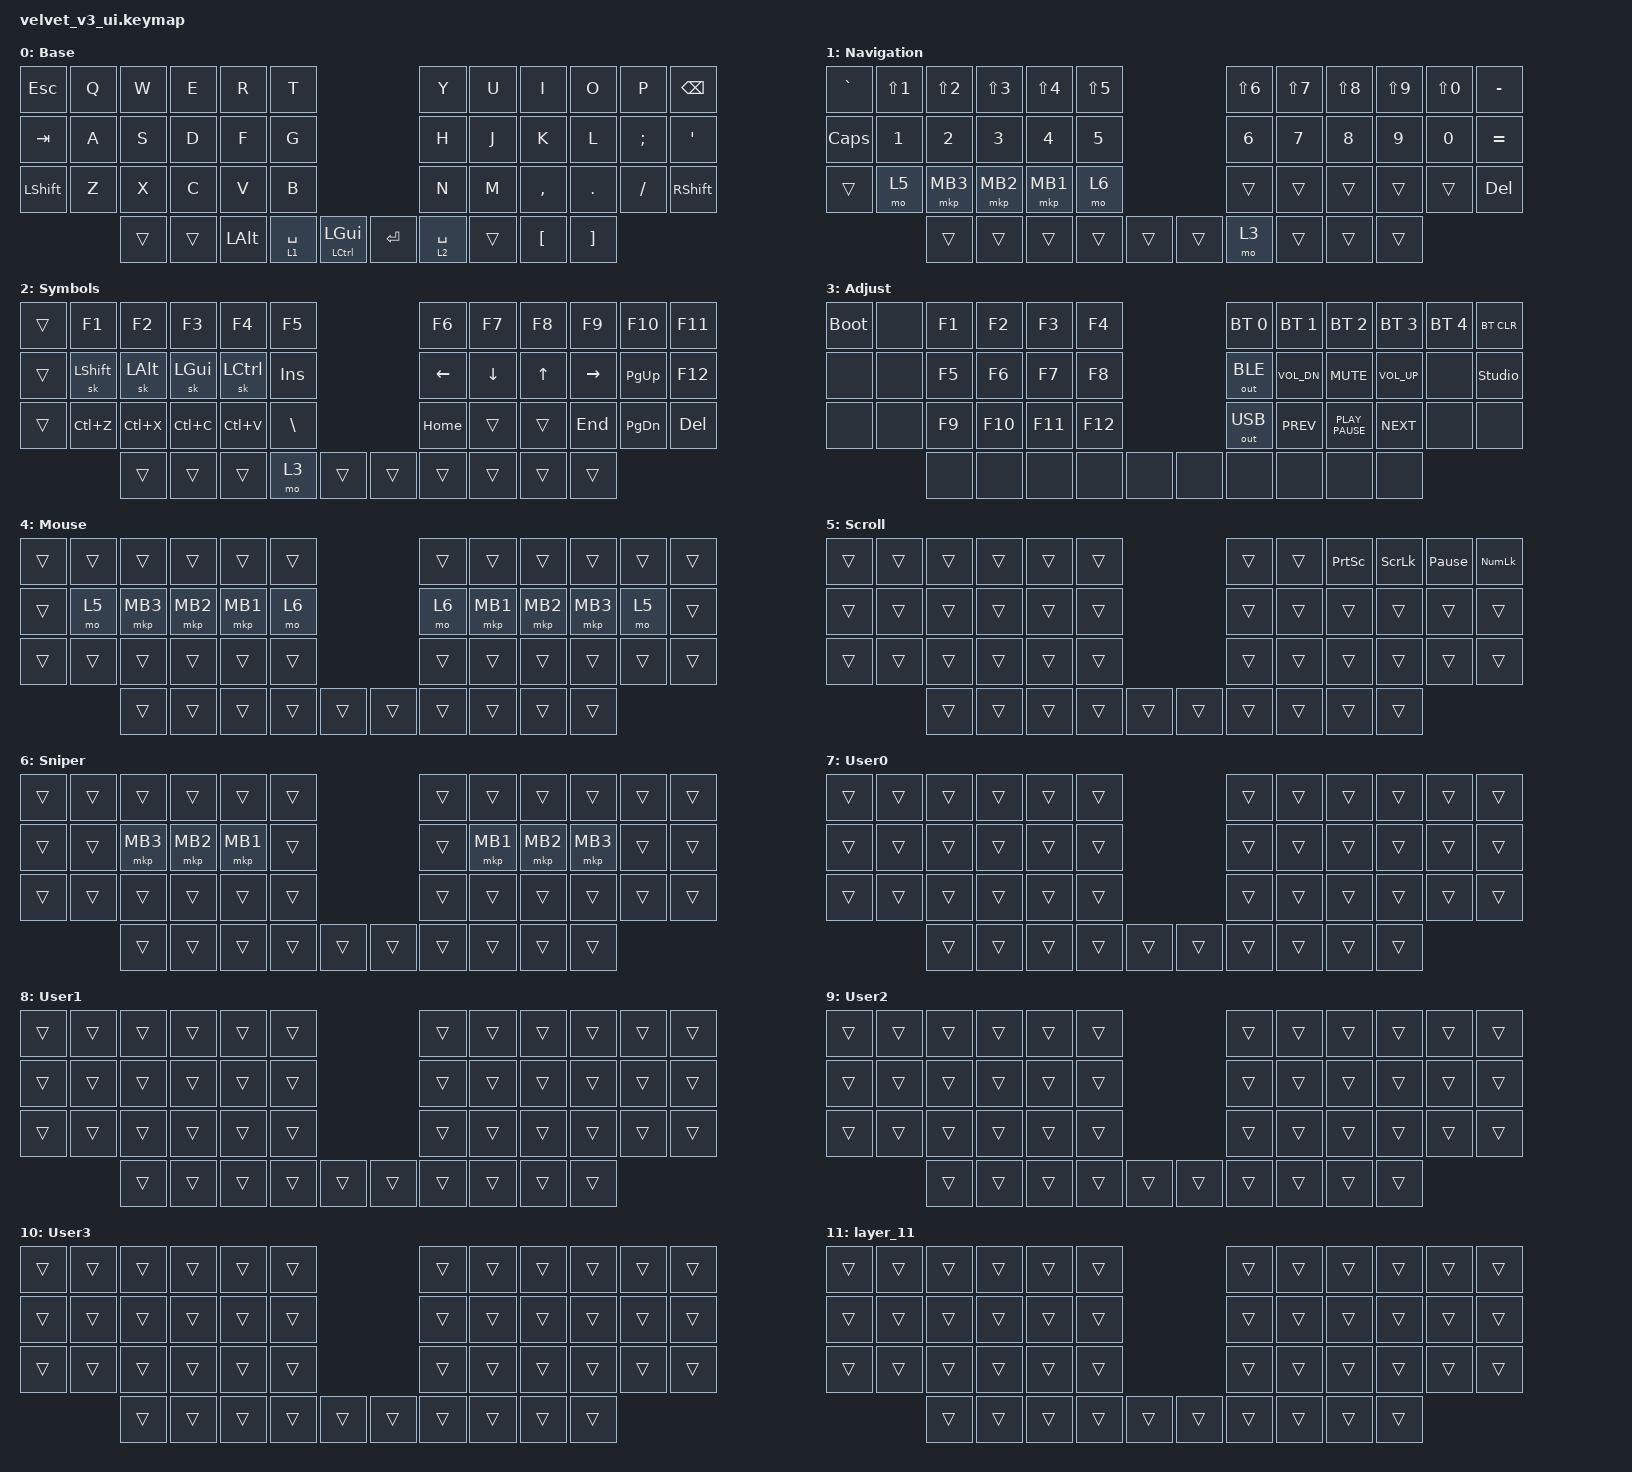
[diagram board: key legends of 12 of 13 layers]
#include "keys_ru.h"
#include <dt-bindings/zmk/input_transform.h>
#include <input/processors.dtsi>
#include <zephyr/dt-bindings/input/input-event-codes.h>
#include <behaviors.dtsi>
#include <dt-bindings/zmk/bt.h>
#include <dt-bindings/zmk/keys.h>
#include <dt-bindings/zmk/outputs.h>
#include <dt-bindings/zmk/pointing.h>

/ {
    behaviors {
        cap_sen: cap_sen {
            compatible = "zmk,behavior-hold-tap";
            label = "CAP_SEN";
            bindings = <&mo>, <&mkp>;

            #binding-cells = <2>;
            tapping-term-ms = <150>;
            hold-while-undecided;
        };
    };

    combos {
        compatible = "zmk,combos";

        en_ru {
            bindings = <&kp LG(SPACE)>;
            key-positions = <19 20>;
        };

        left_br {
            bindings = <&kp LEFT_BRACKET>;
            key-positions = <7 8>;
        };

        rigth_br {
            bindings = <&kp RIGHT_BRACKET>;
            key-positions = <8 9>;
        };
    };

    keymap {
        compatible = "zmk,keymap";

        Base {
            bindings = <
&kp ESC    &kp Q  &kp W   &kp E   &kp R         &kp T                                       &kp Y        &kp U   &kp I      &kp O     &kp P      &kp BSPC
&kp TAB    &kp A  &kp S   &kp D   &kp F         &kp G                                       &kp H        &kp J   &kp K      &kp L     &kp SEMI   &kp SINGLE_QUOTE
&kp LSHFT  &kp Z  &kp X   &kp C   &kp V         &kp B                                       &kp N        &kp M   &kp COMMA  &kp DOT   &kp SLASH  &kp RSHFT
                  &trans  &trans  &kp LEFT_ALT  &lt 1 SPACE  &mt LCTRL LEFT_GUI    &kp RET  &lt 2 SPACE  &trans  &kp LBKT   &kp RBKT
            >;

            display-name = "Base";
        };

        Navigation {
            bindings = <
&kp GRAVE  &kp LS(N1)    &kp LS(N2)    &kp LS(N3)    &kp LS(N4)    &kp LS(N5)                      &kp LS(N6)    &kp LS(N7)    &kp LS(N8)    &kp LS(N9)    &kp LS(N0)    &kp MINUS
&kp CAPS   &kp NUMBER_1  &kp NUMBER_2  &kp NUMBER_3  &kp NUMBER_4  &kp NUMBER_5                    &kp NUMBER_6  &kp NUMBER_7  &kp NUMBER_8  &kp NUMBER_9  &kp NUMBER_0  &kp EQUAL
&trans     &mo 5         &mkp MB3      &mkp MB2      &mkp MB1      &mo 6                           &trans        &trans        &trans        &trans        &trans        &kp DELETE
                         &trans        &trans        &trans        &trans        &trans    &trans  &mo 3         &trans        &trans        &trans
            >;

            display-name = "Navigation";
        };

        Symbols {
            bindings = <
&trans  &kp F1          &kp F2        &kp F3        &kp F4     &kp F5                           &kp F6    &kp F7    &kp F8  &kp F9     &kp F10        &kp F11
&trans  &sk LEFT_SHIFT  &sk LEFT_ALT  &sk LEFT_GUI  &sk LCTRL  &kp INSERT                       &kp LEFT  &kp DOWN  &kp UP  &kp RIGHT  &kp PAGE_UP    &kp F12
&trans  &kp LC(Z)       &kp LC(X)     &kp LC(C)     &kp LC(V)  &kp BACKSLASH                    &kp HOME  &trans    &trans  &kp END    &kp PAGE_DOWN  &kp DELETE
                        &trans        &trans        &trans     &mo 3          &trans    &trans  &trans    &trans    &trans  &trans
            >;

            display-name = "Symbols";
        };

        Adjust {
            bindings = <
&bootloader  &none  &kp F1  &kp F2   &kp F3   &kp F4                   &bt BT_SEL 0  &bt BT_SEL 1  &bt BT_SEL 2      &bt BT_SEL 3  &bt BT_SEL 4  &bt BT_CLR
&none        &none  &kp F5  &kp F6   &kp F7   &kp F8                   &out OUT_BLE  &kp C_VOL_DN  &kp K_MUTE        &kp C_VOL_UP  &none         &studio_unlock
&none        &none  &kp F9  &kp F10  &kp F11  &kp F12                  &out OUT_USB  &kp K_PREV    &kp K_PLAY_PAUSE  &kp K_NEXT    &none         &none
                    &none   &none    &none    &none    &none    &none  &none         &none         &none             &none
            >;

            display-name = "Adjust";
        };

        Mouse {
            bindings = <
&trans  &trans  &trans    &trans    &trans    &trans                    &trans  &trans    &trans    &trans    &trans  &trans
&trans  &mo 5   &mkp MB3  &mkp MB2  &mkp MB1  &mo 6                     &mo 6   &mkp MB1  &mkp MB2  &mkp MB3  &mo 5   &trans
&trans  &trans  &trans    &trans    &trans    &trans                    &trans  &trans    &trans    &trans    &trans  &trans
                &trans    &trans    &trans    &trans  &trans    &trans  &trans  &trans    &trans    &trans
            >;
        };

        Scroll {
            bindings = <
&trans  &trans  &trans  &trans  &trans  &trans                    &trans  &trans  &kp PRINTSCREEN  &kp SCROLLLOCK  &kp PAUSE_BREAK  &kp KP_NUMLOCK
&trans  &trans  &trans  &trans  &trans  &trans                    &trans  &trans  &trans           &trans          &trans           &trans
&trans  &trans  &trans  &trans  &trans  &trans                    &trans  &trans  &trans           &trans          &trans           &trans
                &trans  &trans  &trans  &trans  &trans    &trans  &trans  &trans  &trans           &trans
            >;
        };

        Sniper {
            bindings = <
&trans  &trans  &trans    &trans    &trans    &trans                    &trans  &trans    &trans    &trans    &trans  &trans
&trans  &trans  &mkp MB3  &mkp MB2  &mkp MB1  &trans                    &trans  &mkp MB1  &mkp MB2  &mkp MB3  &trans  &trans
&trans  &trans  &trans    &trans    &trans    &trans                    &trans  &trans    &trans    &trans    &trans  &trans
                &trans    &trans    &trans    &trans  &trans    &trans  &trans  &trans    &trans    &trans
            >;
        };

        User0 {
            bindings = <
&trans  &trans  &trans  &trans  &trans  &trans                    &trans  &trans  &trans  &trans  &trans  &trans
&trans  &trans  &trans  &trans  &trans  &trans                    &trans  &trans  &trans  &trans  &trans  &trans
&trans  &trans  &trans  &trans  &trans  &trans                    &trans  &trans  &trans  &trans  &trans  &trans
                &trans  &trans  &trans  &trans  &trans    &trans  &trans  &trans  &trans  &trans
            >;

            display-name = "User0";
        };

        User1 {
            bindings = <
&trans  &trans  &trans  &trans  &trans  &trans                    &trans  &trans  &trans  &trans  &trans  &trans
&trans  &trans  &trans  &trans  &trans  &trans                    &trans  &trans  &trans  &trans  &trans  &trans
&trans  &trans  &trans  &trans  &trans  &trans                    &trans  &trans  &trans  &trans  &trans  &trans
                &trans  &trans  &trans  &trans  &trans    &trans  &trans  &trans  &trans  &trans
            >;

            display-name = "User1";
        };

        User2 {
            bindings = <
&trans  &trans  &trans  &trans  &trans  &trans                    &trans  &trans  &trans  &trans  &trans  &trans
&trans  &trans  &trans  &trans  &trans  &trans                    &trans  &trans  &trans  &trans  &trans  &trans
&trans  &trans  &trans  &trans  &trans  &trans                    &trans  &trans  &trans  &trans  &trans  &trans
                &trans  &trans  &trans  &trans  &trans    &trans  &trans  &trans  &trans  &trans
            >;

            display-name = "User2";
        };

        User3 {
            bindings = <
&trans  &trans  &trans  &trans  &trans  &trans                    &trans  &trans  &trans  &trans  &trans  &trans
&trans  &trans  &trans  &trans  &trans  &trans                    &trans  &trans  &trans  &trans  &trans  &trans
&trans  &trans  &trans  &trans  &trans  &trans                    &trans  &trans  &trans  &trans  &trans  &trans
                &trans  &trans  &trans  &trans  &trans    &trans  &trans  &trans  &trans  &trans
            >;

            display-name = "User3";
        };

        layer_11 {
            bindings = <
&trans  &trans  &trans  &trans  &trans  &trans                    &trans  &trans  &trans  &trans  &trans  &trans
&trans  &trans  &trans  &trans  &trans  &trans                    &trans  &trans  &trans  &trans  &trans  &trans
&trans  &trans  &trans  &trans  &trans  &trans                    &trans  &trans  &trans  &trans  &trans  &trans
                &trans  &trans  &trans  &trans  &trans    &trans  &trans  &trans  &trans  &trans
            >;
        };

        layer_12 {
            bindings = <
&trans  &trans  &trans  &trans  &trans  &trans                    &trans  &trans  &trans  &trans  &trans  &trans
&trans  &trans  &trans  &trans  &trans  &trans                    &trans  &trans  &trans  &trans  &trans  &trans
&trans  &trans  &trans  &trans  &trans  &trans                    &trans  &trans  &trans  &trans  &trans  &trans
                &trans  &trans  &trans  &trans  &trans    &trans  &trans  &trans  &trans  &trans
            >;
        };
    };
};

&trackball { cpi = <1000>; };

&trackball_listener {
    input-processors = <&zip_xy_scaler 9 20>;

    scroller {
        layers = <5>;
        input-processors =
            <&zip_xy_transform INPUT_TRANSFORM_Y_INVERT>,
            <&zip_xy_scaler 1 32>,
            <&zip_xy_to_scroll_mapper>;
    };

    sniper {
        layers = <6>;
        input-processors = <&zip_xy_scaler 1 4>;
    };
};
